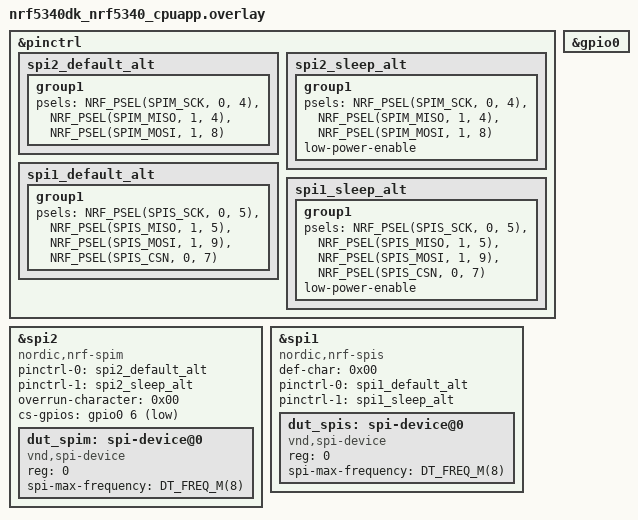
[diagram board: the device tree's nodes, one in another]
/*
 * SPDX-FileCopyrightText: Copyright 2026 Nordic Semiconductor ASA
 *
 * SPDX-License-Identifier: Apache-2.0
 */

/*
 * SPIM (spi2) <-> SPIS (spi1) loopback, required connections:
 *
 * SCK  = P0.04 <-> P0.05
 * MISO = P1.04 <-> P1.05
 * MOSI = P1.08 <-> P1.09
 * CSN  = P0.06 <-> P0.07
 */

&pinctrl {
	spi2_default_alt: spi2_default_alt {
		group1 {
			psels = <NRF_PSEL(SPIM_SCK, 0, 4)>,
				<NRF_PSEL(SPIM_MISO, 1, 4)>,
				<NRF_PSEL(SPIM_MOSI, 1, 8)>;
		};
	};

	spi2_sleep_alt: spi2_sleep_alt {
		group1 {
			psels = <NRF_PSEL(SPIM_SCK, 0, 4)>,
				<NRF_PSEL(SPIM_MISO, 1, 4)>,
				<NRF_PSEL(SPIM_MOSI, 1, 8)>;
			low-power-enable;
		};
	};

	spi1_default_alt: spi1_default_alt {
		group1 {
			psels = <NRF_PSEL(SPIS_SCK, 0, 5)>,
				<NRF_PSEL(SPIS_MISO, 1, 5)>,
				<NRF_PSEL(SPIS_MOSI, 1, 9)>,
				<NRF_PSEL(SPIS_CSN, 0, 7)>;
		};
	};

	spi1_sleep_alt: spi1_sleep_alt {
		group1 {
			psels = <NRF_PSEL(SPIS_SCK, 0, 5)>,
				<NRF_PSEL(SPIS_MISO, 1, 5)>,
				<NRF_PSEL(SPIS_MOSI, 1, 9)>,
				<NRF_PSEL(SPIS_CSN, 0, 7)>;
			low-power-enable;
		};
	};
};

&gpio0 {
	status = "okay";
};

&spi2 {
	compatible = "nordic,nrf-spim";
	status = "okay";
	pinctrl-0 = <&spi2_default_alt>;
	pinctrl-1 = <&spi2_sleep_alt>;
	pinctrl-names = "default", "sleep";
	overrun-character = <0x00>;
	cs-gpios = <&gpio0 6 GPIO_ACTIVE_LOW>;

	dut_spim: spi-device@0 {
		compatible = "vnd,spi-device";
		reg = <0>;
		spi-max-frequency = <DT_FREQ_M(8)>;
	};
};

&spi1 {
	compatible = "nordic,nrf-spis";
	status = "okay";
	def-char = <0x00>;
	pinctrl-0 = <&spi1_default_alt>;
	pinctrl-1 = <&spi1_sleep_alt>;
	pinctrl-names = "default", "sleep";

	dut_spis: spi-device@0 {
		compatible = "vnd,spi-device";
		reg = <0>;
		spi-max-frequency = <DT_FREQ_M(8)>;
	};
};
